# STM32H7RSxx register map
File version: 0.2
CPU: CM7 r0p1, little endian, MPU, FPU, 4 interrupt priority bits
Registers are 32-bit, read-write, reset 0x0 unless marked. A register's access mark holds for its fields unless they carry their own. Offsets are from the block's base; [hi:lo] are bit positions; {n}, {i} and the like mark numbered series.

## DMA2D — Chrom-Art Accelerator controller
Base 0x52001000
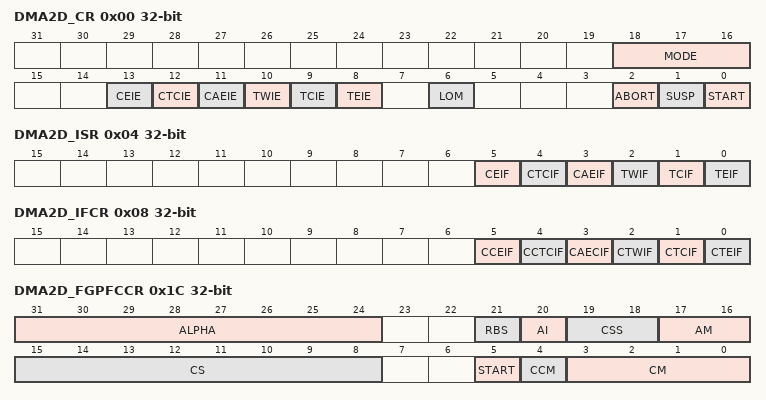
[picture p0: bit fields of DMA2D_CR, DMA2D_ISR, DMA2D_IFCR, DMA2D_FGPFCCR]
0x00 DMA2D_CR — DMA2D control register
  [18:16] MODE — DMA2D mode This bit is set and cleared by software. It cannot be modified while a transfer is ongoing. Others: Reserved
    0=Memory-to-memory (FG fetch only); 1=Memory-to-memory with PFC (FG fetch only with FG PFC active); 2=Memory-to-memory with blending (FG and BG fetch with PFC and blending); 3=Register-to-memory (no FG nor BG, only output stage active); 4=Memory-to-memory with blending and fixed color FG (BG fetch only with FG and BG PFC active); 5=Memory-to-memory with blending and fixed color BG (FG fetch only with FG and BG PFC active)
  [13] CEIE — Configuration error (CE) interrupt enable This bit is set and cleared by software.
    0=CE interrupt disabled; 1=CE interrupt enabled
  [12] CTCIE — CLUT transfer complete (CTC) interrupt enable This bit is set and cleared by software.
    0=CTC interrupt disabled; 1=CTC interrupt enabled
  [11] CAEIE — CLUT access error (CAE) interrupt enable This bit is set and cleared by software.
    0=CAE interrupt disabled; 1=CAE interrupt enabled
  [10] TWIE — Transfer watermark (TW) interrupt enable This bit is set and cleared by software.
    0=TW interrupt disabled; 1=TW interrupt enabled
  [9] TCIE — Transfer complete (TC) interrupt enable This bit is set and cleared by software.
    0=TC interrupt disabled; 1=TC interrupt enabled
  [8] TEIE — Transfer error (TE) interrupt enable This bit is set and cleared by software.
    0=TE interrupt disabled; 1=TE interrupt enabled
  [6] LOM — Line offset mode This bit configures how the line offset is expressed (pixels or bytes) for the foreground, background and output. This bit is set and cleared by software. It can not be modified while a transfer is ongoing.
    0=Line offsets expressed in pixels; 1=Line offsets expressed in bytes
  [2] ABORT — Abort This bit can be used to abort the current transfer. This bit is set by software, and is automatically reset by hardware when START = 0.
    0=No transfer abort requested; 1=Transfer abort requested
  [1] SUSP — Suspend This bit can be used to suspend the current transfer. This bit is set and reset by software. It is automatically reset by hardware when START = 0.
    0=Transfer not suspended; 1=Transfer suspended
  [0] START — Start This bit can be used to launch the DMA2D according to parameters loaded in the various configuration registers. This bit is automatically reset by the following events: at the end of the transfer when the data transfer is aborted by the user by setting ABORT in this register when a data transfer error occurs when the data transfer has not started due to a configuration error, or another transfer operation already ongoing (automatic CLUT loading)
0x04 DMA2D_ISR ro — DMA2D interrupt status register
  [5] CEIF — Configuration error interrupt flag This bit is set when START is set in DMA2D_CR, DMA2DFGPFCCR or DMA2D_BGPFCCR, and a wrong configuration has been programmed.
  [4] CTCIF — CLUT transfer complete interrupt flag This bit is set when the CLUT copy from a system memory area to the internal DMA2D memory is complete.
  [3] CAEIF — CLUT access error interrupt flag This bit is set when the CPU accesses the CLUT while the CLUT is being automatically copied from a system memory to the internal DMA2D.
  [2] TWIF — Transfer watermark interrupt flag This bit is set when the last pixel of the watermarked line has been transferred.
  [1] TCIF — Transfer complete interrupt flag This bit is set when a DMA2D transfer operation is complete (data transfer only).
  [0] TEIF — Transfer error interrupt flag This bit is set when an error occurs during a DMA transfer (data transfer or automatic CLUT loading).
0x08 DMA2D_IFCR — DMA2D interrupt flag clear register
  [5] CCEIF — Clear configuration error interrupt flag Programming this bit to 1 clears the CEIF flag in DMA2D_ISR.
  [4] CCTCIF — Clear CLUT transfer complete interrupt flag Programming this bit to 1 clears the CTCIF flag in DMA2D_ISR.
  [3] CAECIF — Clear CLUT access error interrupt flag Programming this bit to 1 clears the CAEIF flag in DMA2D_ISR.
  [2] CTWIF — Clear transfer watermark interrupt flag Programming this bit to 1 clears the TWIF flag in DMA2D_ISR.
  [1] CTCIF — Clear transfer complete interrupt flag Programming this bit to 1 clears the TCIF flag in DMA2D_ISR.
  [0] CTEIF — Clear transfer error interrupt flag Programming this bit to 1 clears the TEIF flag in DMA2D_ISR.
0x0C DMA2D_FGMAR — DMA2D foreground memory address register
  [31:0] MA — Memory address, address of the data used for the foreground image The address alignment must match the image format selected: a 32-bit per pixel format must be 32-bit aligned, a 16-bit per pixel format must be 16-bit aligned, and a 4-bit per pixel format must be 8-bit aligned.
0x10 DMA2D_FGOR — DMA2D foreground offset register
  [15:0] LO — Line offset This field gives the line offset used for the foreground image, expressed: in pixels when LOM = 0 in DMA2D_CR. Only LO[13:0] bits are considered, LO[15:14] bits are ignored. in bytes when LOM = 1 This value is used for the address generation. It is added at the end of each line to determine the starting address of the next line. If the image format is 4-bit per pixel, the line offset must be even.
0x14 DMA2D_BGMAR — DMA2D background memory address register
  [31:0] MA — Memory address, address of the data used for the background image The address alignment must match the image format selected: a 32-bit per pixel format must be 32-bit aligned, a 16-bit per pixel format must be 16-bit aligned and a 4-bit per pixel format must be 8-bit aligned.
0x18 DMA2D_BGOR — DMA2D background offset register
  [15:0] LO — Line offset This field gives the line offset used for the background image, expressed: in pixels when LOM = 0 in DMA2D_CR. Only LO[13:0] bits are considered, LO[15:14] bits are ignored. in bytes when LOM = 1 This value is used for the address generation. It is added at the end of each line to determine the starting address of the next line. If the image format is 4-bit per pixel, the line offset must be even.
0x1C DMA2D_FGPFCCR — DMA2D foreground PFC control register
  [31:24] ALPHA — Alpha value These bits define a fixed alpha channel value which can replace the original alpha value, or be multiplied by the original alpha value, according to the alpha mode selected through AM[1:0] in this register.
  [21] RBS — Red/Blue swap This bit allows to swap Red and Blue to support BGR or ABGR color formats.
    0=Regular mode (RGB or ARGB); 1=Swap mode (BGR or ABGR)
  [20] AI — Alpha inverted This bit inverts the alpha value.
    0=Regular alpha; 1=Inverted alpha
  [19:18] CSS — Chroma subsampling These bits define the chroma subsampling mode for YCbCr color mode. Others: Reserved
    0=4:4:4 (no chroma subsampling); 1=4:2:2; 2=4:2:0
  [17:16] AM — Alpha mode These bits select the alpha channel value to be used for the foreground image. Others: Reserved
    0=No modification of the foreground image alpha channel value; 1=Replace original foreground image alpha channel value by ALPHA[7: 0]; 2=Replace original foreground image alpha channel value by ALPHA[7:0] multiplied with original alpha channel value
  [15:8] CS — CLUT size These bits define the size of the CLUT used for the foreground image. The number of CLUT entries is equal to CS[7:0] + 1.
  [5] START — Start This bit can be set to start the automatic loading of the CLUT. It is automatically reset: at the end of the transfer when the transfer is aborted by the user by setting ABORT in DMA2D_CR when a transfer error occurs when the transfer has not started due to a configuration error or another transfer operation already ongoing (data transfer or automatic background CLUT transfer)
  [4] CCM — CLUT color mode This bit defines the color format of the CLUT.
    0=ARGB8888; 1=RGB888
  [3:0] CM — Color mode These bits defines the color format of the foreground image. Others: Reserved
    0=ARGB8888; 1=RGB888; 2=RGB565; 3=ARGB1555; 4=ARGB4444; 5=L8; 6=AL44; 7=AL88; 8=L4; 9=A8; 10=A4; 11=YCbCr
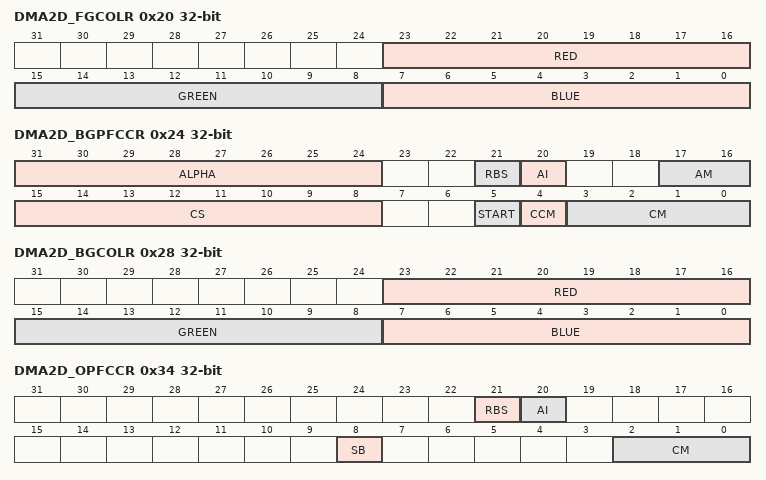
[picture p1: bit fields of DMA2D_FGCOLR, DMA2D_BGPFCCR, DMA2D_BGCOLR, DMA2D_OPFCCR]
0x20 DMA2D_FGCOLR — DMA2D foreground color register
  [23:16] RED — Red value for the A4 or A8 mode of the foreground image Used also for fixed color FG in memory-to-memory mode with blending and fixed color FG (BG fetch only with FG and BG PFC active).
  [15:8] GREEN — Green value for the A4 or A8 mode of the foreground image Used also for fixed color FG in memory-to-memory mode with blending and fixed color FG (BG fetch only with FG and BG PFC active).
  [7:0] BLUE — Blue value for the A4 or A8 mode of the foreground image Used also for fixed color FG in memory-to-memory mode with blending and fixed color FG (BG fetch only with FG and BG PFC active).
0x24 DMA2D_BGPFCCR — DMA2D background PFC control register
  [31:24] ALPHA — Alpha value These bits define a fixed alpha channel value which can replace the original alpha value, or be multiplied with the original alpha value according to the alpha mode selected with AM[1:0].
  [21] RBS — Red/Blue swap This bit allows to swap Red and Blue to support BGR or ABGR color formats.
    0=Regular mode (RGB or ARGB); 1=Swap mode (BGR or ABGR)
  [20] AI — Alpha Inverted This bit inverts the alpha value.
    0=Regular alpha; 1=Inverted alpha
  [17:16] AM — Alpha mode These bits define which alpha channel value to be used for the background image. Others: Reserved
    0=No modification of the foreground image alpha channel value; 1=Replace original background image alpha channel value by ALPHA[7: 0]; 2=Replace original background image alpha channel value by ALPHA[7:0] multiplied with original alpha channel value
  [15:8] CS — CLUT size These bits define the size of the CLUT used for the BG. The number of CLUT entries is equal to CS[7:0] + 1.
  [5] START — Start This bit is set to start the automatic loading of the CLUT. This bit is automatically reset: at the end of the transfer when the transfer is aborted by the user by setting ABORT bit in DMA2D_CR when a transfer error occurs when the transfer has not started due to a configuration error or another transfer operation already on going (data transfer or automatic background CLUT transfer)
  [4] CCM — CLUT color mode These bits define the color format of the CLUT.
    0=ARGB8888; 1=RGB888
  [3:0] CM — Color mode These bits define the color format of the foreground image. Others: Reserved
    0=ARGB8888; 1=RGB888; 2=RGB565; 3=ARGB1555; 4=ARGB4444; 5=L8; 6=AL44; 7=AL88; 8=L4; 9=A8; 10=A4
0x28 DMA2D_BGCOLR — DMA2D background color register
  [23:16] RED — Red value for the A4 or A8 mode of the background Used also for fixed color BG in memory-to-memory mode with blending and fixed color BG (FG fetch only with FG and BG PFC active).
  [15:8] GREEN — Green value for the A4 or A8 mode of the background Used also for fixed color BG in memory-to-memory mode with blending and fixed color BG (FG fetch only with FG and BG PFC active).
  [7:0] BLUE — Blue value for the A4 or A8 mode of the background Used also for fixed color BG in memory-to-memory mode with blending and fixed color BG (FG fetch only with FG and BG PFC active).
0x2C DMA2D_FGCMAR — DMA2D foreground CLUT memory address register
  [31:0] MA — Memory address Address of the data used for the CLUT address dedicated to the foreground image. If the foreground CLUT format is 32-bit, the address must be 32-bit aligned.
0x30 DMA2D_BGCMAR — DMA2D background CLUT memory address register
  [31:0] MA — Memory address Address of the data used for the CLUT address dedicated to the background image. If the background CLUT format is 32-bit, the address must be 32-bit aligned.
0x34 DMA2D_OPFCCR — DMA2D output PFC control register
  [21] RBS — Red/Blue swap This bit allows to swap Red and Blue to support BGR or ABGR color formats.
    0=Regular mode (RGB or ARGB); 1=Swap mode (BGR or ABGR)
  [20] AI — Alpha Inverted This bit inverts the alpha value.
    0=Regular alpha; 1=Inverted alpha
  [8] SB — Swap bytes When this bit is set, the bytes in the output FIFO are swapped two by two. The number of pixels per line (PL) must be even, and the output memory address (OMAR) must be even.
    0=Bytes in regular order in the output FIFO; 1=Bytes swapped two by two in the output FIFO
  [2:0] CM — Color mode These bits define the color format of the output image. Others: Reserved
    0=ARGB8888; 1=RGB888; 2=RGB565; 3=ARGB1555; 4=ARGB4444
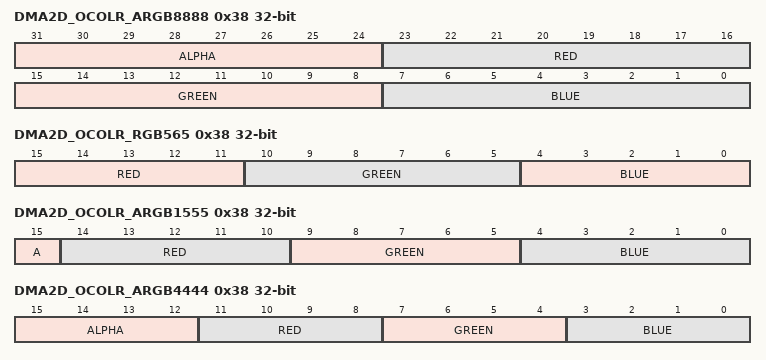
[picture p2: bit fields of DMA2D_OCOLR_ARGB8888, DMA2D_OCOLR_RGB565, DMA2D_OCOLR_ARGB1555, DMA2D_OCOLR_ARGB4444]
0x38 DMA2D_OCOLR_ARGB8888 — DMA2D output color register
  [31:24] ALPHA — Alpha channel value of the output color in ARGB8888 mode (otherwise reserved)
  [23:16] RED — Red value of the output image in ARGB8888 or RGB888 mode
  [15:8] GREEN — Green value of the output image in ARGB8888 or RGB888
  [7:0] BLUE — Blue value of the output image in ARGB8888 or RGB888
0x38 DMA2D_OCOLR_RGB565 (alternate view of DMA2D_OCOLR_ARGB8888) — DMA2D output color register
  [15:11] RED — Red value of the output image in RGB565 mode
  [10:5] GREEN — Green value of the output image in RGB565 mode
  [4:0] BLUE — Blue value of the output image in RGB565 mode
0x38 DMA2D_OCOLR_ARGB1555 (alternate view of DMA2D_OCOLR_ARGB8888) — DMA2D output color register
  [15] A — Alpha channel value of the output color in ARGB1555 mode
  [14:10] RED — Red value of the output image in ARGB1555 mode
  [9:5] GREEN — Green value of the output image in ARGB1555 mode
  [4:0] BLUE — Blue value of the output image in ARGB1555 mode
0x38 DMA2D_OCOLR_ARGB4444 (alternate view of DMA2D_OCOLR_ARGB8888) — DMA2D output color register
  [15:12] ALPHA — Alpha channel of the output color value in ARGB4444
  [11:8] RED — Red value of the output image in ARGB4444 mode
  [7:4] GREEN — Green value of the output image in ARGB4444 mode
  [3:0] BLUE — Blue value of the output image in ARGB4444 mode
0x3C DMA2D_OMAR — DMA2D output memory address register
  [31:0] MA — Memory address Address of the data used for the output FIFO. The address alignment must match the image format selected: a 32-bit per pixel format must be 32-bit aligned and a 16-bit per pixel format must be 16-bit aligned.
0x40 DMA2D_OOR — DMA2D output offset register
  [15:0] LO — Line offset This field gives the line offset used for the output, expressed: in pixels when LOM = 0 in DMA2D_CR. Only LO[13:0] bits are considered, LO[15:14] bits are ignored. in bytes when LOM = 1 This value is used for the address generation. It is added at the end of each line to determine the starting address of the next line.
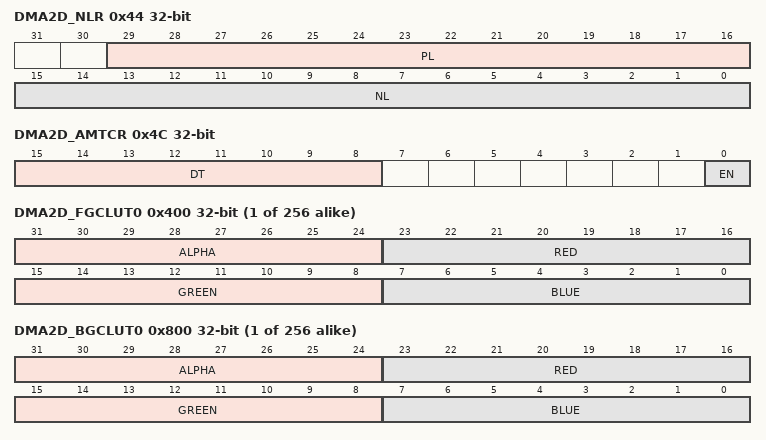
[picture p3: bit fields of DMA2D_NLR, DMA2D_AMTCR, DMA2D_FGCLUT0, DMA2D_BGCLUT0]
0x44 DMA2D_NLR — DMA2D number of line register
  [29:16] PL — Pixel per lines per lines of the area to be transferred If any of the input image format is 4-bit per pixel, pixel per lines must be even.
  [15:0] NL — Number of lines of the area to be transferred.
0x48 DMA2D_LWR — DMA2D line watermark register
  [15:0] LW — Line watermark for interrupt generation An interrupt is raised when the last pixel of the watermarked line has been transferred.
0x4C DMA2D_AMTCR — DMA2D AXI master timer configuration register
  [15:8] DT — Dead time Dead time value in the AXI clock cycle inserted between two consecutive accesses on the AXI master port. These bits represent the minimum guaranteed number of cycles between two consecutive AXI accesses.
  [0] EN — Dead-time functionality enable
{0x400+4i} DMA2D_FGCLUT{i} reset not defined (i=0..255) — DMA2D foreground CLUT
  [31:24] ALPHA — Alpha Alpha value for index {i} for the foreground
  [23:16] RED — Red Red value for index {i} for the foreground
  [15:8] GREEN — Green Green value for index {i} for the foreground
  [7:0] BLUE — Blue Blue value for index {i} for the foreground
{0x800+4i} DMA2D_BGCLUT{i} reset not defined (i=0..255) — DMA2D background CLUT
  [31:24] ALPHA — Alpha Alpha value for index {i} for the background
  [23:16] RED — Red Red value for index {i} for the background
  [15:8] GREEN — Green Green value for index {i} for the background
  [7:0] BLUE — Blue Blue value for index {i} for the background
